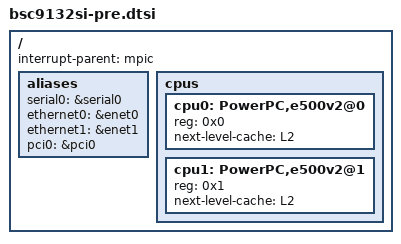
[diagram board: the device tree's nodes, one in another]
/dts-v1/;
/include/ "e500v2_power_isa.dtsi"
/ {
	#address-cells = <2>;
	#size-cells = <2>;
	interrupt-parent = <&mpic>;
	aliases {
		serial0 = &serial0;
		ethernet0 = &enet0;
		ethernet1 = &enet1;
		pci0 = &pci0;
	};
	cpus {
		#address-cells = <1>;
		#size-cells = <0>;
		cpu0: PowerPC,e500v2@0 {
			device_type = "cpu";
			reg = <0x0>;
			next-level-cache = <&L2>;
		};
		cpu1: PowerPC,e500v2@1 {
			device_type = "cpu";
			reg = <0x1>;
			next-level-cache = <&L2>;
		};
	};
};
